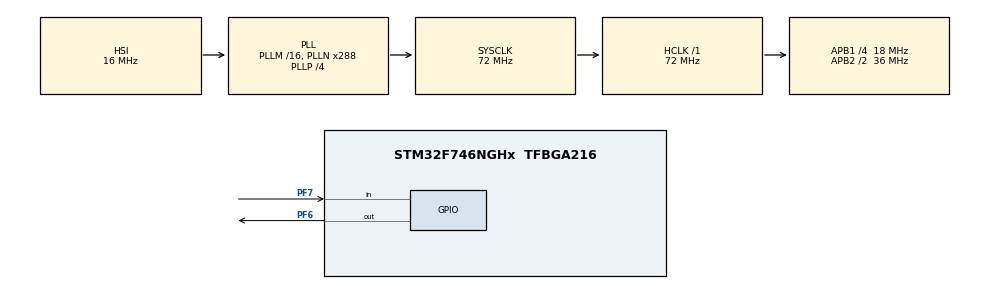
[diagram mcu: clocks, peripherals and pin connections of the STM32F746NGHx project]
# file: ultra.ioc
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CORTEX_M7.ART_ACCLERATOR_ENABLE=0
CORTEX_M7.CPU_DCache=Disabled
CORTEX_M7.CPU_ICache=Disabled
CORTEX_M7.PREFETCH_ENABLE=0
Mcu.Family=STM32F7
Mcu.Name=STM32F746NGHx
Mcu.Package=TFBGA216
NVIC.PriorityGroup=NVIC_PRIORITYGROUP_4
NVIC.RCC_IRQn=true\:0\:0\:false\:false\:true\:true
NVIC.TIM2_IRQn=true\:0\:0\:false\:true\:true\:1\:true
PA13.Mode=Serial_Wire
PA13.Signal=SYS_JTMS-SWDIO
PA14.Mode=Serial_Wire
PA14.Signal=SYS_JTCK-SWCLK
PF6.GPIO_Speed=GPIO_SPEED_FREQ_HIGH
PF6.Signal=GPIO_Output
PF7.GPIO_PuPd=GPIO_PULLDOWN
PF7.Signal=GPIO_Input
PH0/OSC_IN.Mode=HSE-External-Oscillator
PH0/OSC_IN.Signal=RCC_OSC_IN
PH1/OSC_OUT.Mode=HSE-External-Oscillator
PH1/OSC_OUT.Signal=RCC_OSC_OUT
ProjectManager.HeapSize=0x200
ProjectManager.StackSize=0x400
ProjectManager.TargetToolchain=MDK-ARM V5
RCC.AHBFreq_Value=72000000
RCC.APB1CLKDivider=RCC_HCLK_DIV4
RCC.APB1Freq_Value=18000000
RCC.APB1TimFreq_Value=36000000
RCC.APB2CLKDivider=RCC_HCLK_DIV2
RCC.APB2Freq_Value=36000000
RCC.APB2TimFreq_Value=72000000
RCC.CortexFreq_Value=72000000
RCC.HCLKFreq_Value=72000000
RCC.HSE_VALUE=25000000
RCC.HSI_VALUE=16000000
RCC.LSE_VALUE=32768
RCC.PLLN=288
RCC.PLLP=RCC_PLLP_DIV4
RCC.PLLSourceVirtual=RCC_PLLSOURCE_HSI
RCC.SYSCLKFreq_VALUE=72000000
RCC.SYSCLKSource=RCC_SYSCLKSOURCE_PLLCLK
RCC.USBFreq_Value=144000000
RCC.VCOOutputFreq_Value=288000000
TIM2.Period=1000000
TIM2.Prescaler=108
VP_TIM2_VS_ClockSourceINT.Mode=Internal
board=32F746GDISCOVERY

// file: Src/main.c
/**
  ******************************************************************************
  * @file           : main.c
  * @brief          : Main program body
  ******************************************************************************
  ** This notice applies to any and all portions of this file
  * that are not between comment pairs USER CODE BEGIN and
  * USER CODE END. Other portions of this file, whether
  * inserted by the user or by software development tools
  * are owned by their respective copyright owners.
  *
  * COPYRIGHT(c) 2018 STMicroelectronics
  *
  * Redistribution and use in source and binary forms, with or without modification,
  * are permitted provided that the following conditions are met:
  *   1. Redistributions of source code must retain the above copyright notice,
  *      this list of conditions and the following disclaimer.
  *   2. Redistributions in binary form must reproduce the above copyright notice,
  *      this list of conditions and the following disclaimer in the documentation
  *      and/or other materials provided with the distribution.
  *   3. Neither the name of STMicroelectronics nor the names of its contributors
  *      may be used to endorse or promote products derived from this software
  *      without specific prior written permission.
  *
  * THIS SOFTWARE IS PROVIDED BY THE COPYRIGHT HOLDERS AND CONTRIBUTORS "AS IS"
  * AND ANY EXPRESS OR IMPLIED WARRANTIES, INCLUDING, BUT NOT LIMITED TO, THE
  * IMPLIED WARRANTIES OF MERCHANTABILITY AND FITNESS FOR A PARTICULAR PURPOSE ARE
  * DISCLAIMED. IN NO EVENT SHALL THE COPYRIGHT HOLDER OR CONTRIBUTORS BE LIABLE
  * FOR ANY DIRECT, INDIRECT, INCIDENTAL, SPECIAL, EXEMPLARY, OR CONSEQUENTIAL
  * DAMAGES (INCLUDING, BUT NOT LIMITED TO, PROCUREMENT OF SUBSTITUTE GOODS OR
  * SERVICES; LOSS OF USE, DATA, OR PROFITS; OR BUSINESS INTERRUPTION) HOWEVER
  * CAUSED AND ON ANY THEORY OF LIABILITY, WHETHER IN CONTRACT, STRICT LIABILITY,
  * OR TORT (INCLUDING NEGLIGENCE OR OTHERWISE) ARISING IN ANY WAY OUT OF THE USE
  * OF THIS SOFTWARE, EVEN IF ADVISED OF THE POSSIBILITY OF SUCH DAMAGE.
  *
  ******************************************************************************
  */

#include "main.h"
#include "stm32f7xx_hal.h"
#include "dwt_stm32_delay.h"
#include "Ultrasonic.h"

extern double Obstacle;
TIM_HandleTypeDef htim2;

/* USER CODE BEGIN PV */
/* Private variables ---------------------------------------------------------*/

char buffer[10] = "Hello!\r\n";
/* USER CODE END PV */

void SystemClock_Config(void);
static void MX_GPIO_Init(void);
static void MX_TIM2_Init(void);
static void MX_NVIC_Init(void);

/* USER CODE BEGIN PFP */
/* Private function prototypes -----------------------------------------------*/
/* USER CODE END PFP */

int main(void)
{

  /* MCU Configuration----------------------------------------------------------*/

  /* Reset of all peripherals, Initializes the Flash interface and the Systick. */
  HAL_Init();

  /* Configure the system clock */
  SystemClock_Config();

  /* Initialize all configured peripherals */
  MX_GPIO_Init();
  MX_TIM2_Init();

  /* Initialize interrupts */
  MX_NVIC_Init();
  /* USER CODE BEGIN 2 */
	DWT_Delay_Init();

  /* USER CODE END 2 */

  /* Infinite loop */
  /* USER CODE BEGIN WHILE */
  while (1)
  {
		Obstacle = Get_Ultrasonic_Distance();
		HAL_Delay(10);

  /* USER CODE END WHILE */

  }

}

void SystemClock_Config(void)
{

  RCC_OscInitTypeDef RCC_OscInitStruct;
  RCC_ClkInitTypeDef RCC_ClkInitStruct;

    /**Configure the main internal regulator output voltage
    */
  __HAL_RCC_PWR_CLK_ENABLE();

  __HAL_PWR_VOLTAGESCALING_CONFIG(PWR_REGULATOR_VOLTAGE_SCALE3);

    /**Initializes the CPU, AHB and APB busses clocks
    */
  RCC_OscInitStruct.OscillatorType = RCC_OSCILLATORTYPE_HSI;
  RCC_OscInitStruct.HSIState = RCC_HSI_ON;
  RCC_OscInitStruct.HSICalibrationValue = 16;
  RCC_OscInitStruct.PLL.PLLState = RCC_PLL_ON;
  RCC_OscInitStruct.PLL.PLLSource = RCC_PLLSOURCE_HSI;
  RCC_OscInitStruct.PLL.PLLM = 16;
  RCC_OscInitStruct.PLL.PLLN = 288;
  RCC_OscInitStruct.PLL.PLLP = RCC_PLLP_DIV4;
  RCC_OscInitStruct.PLL.PLLQ = 2;
  if (HAL_RCC_OscConfig(&RCC_OscInitStruct) != HAL_OK)
  {
    _Error_Handler(__FILE__, __LINE__);
  }

    /**Initializes the CPU, AHB and APB busses clocks
    */
  RCC_ClkInitStruct.ClockType = RCC_CLOCKTYPE_HCLK|RCC_CLOCKTYPE_SYSCLK
                              |RCC_CLOCKTYPE_PCLK1|RCC_CLOCKTYPE_PCLK2;
  RCC_ClkInitStruct.SYSCLKSource = RCC_SYSCLKSOURCE_PLLCLK;
  RCC_ClkInitStruct.AHBCLKDivider = RCC_SYSCLK_DIV1;
  RCC_ClkInitStruct.APB1CLKDivider = RCC_HCLK_DIV4;
  RCC_ClkInitStruct.APB2CLKDivider = RCC_HCLK_DIV2;

  if (HAL_RCC_ClockConfig(&RCC_ClkInitStruct, FLASH_LATENCY_2) != HAL_OK)
  {
    _Error_Handler(__FILE__, __LINE__);
  }

    /**Configure the Systick interrupt time
    */
  HAL_SYSTICK_Config(HAL_RCC_GetHCLKFreq()/1000);

    /**Configure the Systick
    */
  HAL_SYSTICK_CLKSourceConfig(SYSTICK_CLKSOURCE_HCLK);

  /* SysTick_IRQn interrupt configuration */
  HAL_NVIC_SetPriority(SysTick_IRQn, 0, 0);
}

/**
  * @brief NVIC Configuration.
  * @retval None
  */
static void MX_NVIC_Init(void)
{
  /* TIM2_IRQn interrupt configuration */
  HAL_NVIC_SetPriority(TIM2_IRQn, 0, 0);
  HAL_NVIC_EnableIRQ(TIM2_IRQn);
}

/* TIM2 init function */
static void MX_TIM2_Init(void)
{

  TIM_ClockConfigTypeDef sClockSourceConfig;
  TIM_MasterConfigTypeDef sMasterConfig;

  htim2.Instance = TIM2;
  htim2.Init.Prescaler = 108;
  htim2.Init.CounterMode = TIM_COUNTERMODE_UP;
  htim2.Init.Period = 1000000;
  htim2.Init.ClockDivision = TIM_CLOCKDIVISION_DIV1;
  htim2.Init.AutoReloadPreload = TIM_AUTORELOAD_PRELOAD_DISABLE;
  if (HAL_TIM_Base_Init(&htim2) != HAL_OK)
  {
    _Error_Handler(__FILE__, __LINE__);
  }

  sClockSourceConfig.ClockSource = TIM_CLOCKSOURCE_INTERNAL;
  if (HAL_TIM_ConfigClockSource(&htim2, &sClockSourceConfig) != HAL_OK)
  {
    _Error_Handler(__FILE__, __LINE__);
  }

  sMasterConfig.MasterOutputTrigger = TIM_TRGO_RESET;
  sMasterConfig.MasterSlaveMode = TIM_MASTERSLAVEMODE_DISABLE;
  if (HAL_TIMEx_MasterConfigSynchronization(&htim2, &sMasterConfig) != HAL_OK)
  {
    _Error_Handler(__FILE__, __LINE__);
  }

}

/** Configure pins as
        * Analog
        * Input
        * Output
        * EVENT_OUT
        * EXTI
*/
static void MX_GPIO_Init(void)
{

  GPIO_InitTypeDef GPIO_InitStruct;

  /* GPIO Ports Clock Enable */
  __HAL_RCC_GPIOA_CLK_ENABLE();
  __HAL_RCC_GPIOH_CLK_ENABLE();
  __HAL_RCC_GPIOF_CLK_ENABLE();

  /*Configure GPIO pin Output Level */
  HAL_GPIO_WritePin(GPIOF, GPIO_PIN_6, GPIO_PIN_RESET);

  /*Configure GPIO pin : PF7 */
  GPIO_InitStruct.Pin = GPIO_PIN_7;
  GPIO_InitStruct.Mode = GPIO_MODE_INPUT;
  GPIO_InitStruct.Pull = GPIO_PULLDOWN;
  HAL_GPIO_Init(GPIOF, &GPIO_InitStruct);

  /*Configure GPIO pin : PF6 */
  GPIO_InitStruct.Pin = GPIO_PIN_6;
  GPIO_InitStruct.Mode = GPIO_MODE_OUTPUT_PP;
  GPIO_InitStruct.Pull = GPIO_NOPULL;
  GPIO_InitStruct.Speed = GPIO_SPEED_FREQ_HIGH;
  HAL_GPIO_Init(GPIOF, &GPIO_InitStruct);

}

void _Error_Handler(char *file, int line)
{
  while(1)
  {
  }
}

/************************ (C) COPYRIGHT STMicroelectronics *****END OF FILE****/
